# nrf9220_cellrf register map
Vendor: Nordic Semiconductor; Series: nRF92; File version: 1
CPU: CM0 r0p0, little endian, no MPU, no FPU, 2 interrupt priority bits, 33 interrupts
Registers are 32-bit, read-write, reset 0x0 unless marked. A register's access mark holds for its fields unless they carry their own. Offsets are from the block's base; [hi:lo] are bit positions; {n}, {i} and the like mark numbered series; 'fields as' and 'values as' point back to an identical list.

## RXDFE (part 2 of 2) — HALTI_RX_register_map AhmaRx Digital control register map Karhu Rx Analog control register map AhmaRx Digital control register map
Base 0x46130000
0x5A8 RX_NBPM_DC_I ro — Measured narrow band DC I.
  [15:0] DC — This is a signed value. This registers can be read after RX_NBPM_READY event is occurred.
0x5AC RX_NBPM_DC_Q ro — Measured narrow band DC Q.
  fields as RX_NBPM_DC_I
0x5B0 RX_WBPM_DATA_SEL — Wide band power meter input data selection.
  [1:0] SEL — Selects input data of wide band power meter.
    0=HBFIR1 (HB FIR 1 input); 1=HBFIR2 (HB FIR 2 input); 2=DCCOMP (DC compensator input)
0x5B4 RX_WBPM_FACTOR_L — Wide band power meter factor L.
  [2:0] FACTOR — Specifies how many bits of input data are downshifted before data is feed into wide band power meter.
    0=0bit; 1=1bit; 7=7bits
0x5B8 RX_WBPM_FACTOR_M — Wide band power meter factor M.
  [5:0] FACTOR — Number of consecutive power measurements on which max power is performed.
    0=1 measurement; 1=2 measurements; 63=64 measurements
0x5BC RX_WBPM_FACTOR_K — Wide band power meter factor K.
  [13:0] FACTOR — Number of samples considered in power and DC measurement (i.e. accumulation).
    0=1sample; 1=2samples; 0x3FFF=16384samples
0x5C0 RX_WBPM_FACTOR_N — Wide band power meter factor N.
  [3:0] FACTOR — Specifies how many bits are downshifted after power and DC accumulation.
    0=0bit; 1=1bit; 15=15bits
0x5C4 RX_WBPM_POWER ro — Measured wide band power.
  [31:0] POWER — This is a squared value. This registers can be read after RX_WBPM_READY event is occurred.
0x5C8 RX_WBPM_DC_I ro — Measured wide band DC I.
  [15:0] DC — This is a signed value. This registers can be read after RX_WBPM_READY event is occurred.
0x5CC RX_WBPM_DC_Q ro — Measured wide band DC Q.
  fields as RX_WBPM_DC_I
0x5D0 RX_SAMPLE_CNT_COMP_0 — RX sample count compare 0.
  [31:0] COMP — When this value matches internal RX sample counter, the RX_SAMPLE_CNT_COMP_0 event is generated.
0x5D4 RX_SAMPLE_CNT_CAPT_0 ro — RX sample count capture 0.
  [31:0] CAPT — The task RX_CAPT_SAMPLE_CNT_0 captures the sample counter value into this register. This registers can be read after RX_SAMPLE_CNT_CAPT_0 event is occurred.
0x5D8 RX_SAMPLE_CNT_COMP_1 — RX sample count compare 1.
  [31:0] COMP — When this value matches internal RX sample counter, the RX_SAMPLE_CNT_COMP_1 event is generated.
0x5DC RX_SAMPLE_CNT_CAPT_1 ro — RX sample count capture 1.
  [31:0] CAPT — The task RX_CAPT_SAMPLE_CNT_1 captures the sample counter value into this register. This registers can be read after RX_SAMPLE_CNT_CAPT_1 event is occurred.
0x5E0 RX_IQ_EST_ENABLE — IQ estimation enable.
  [0] ENABLE — Enable IQ estimation.
    0=Disabled; 1=Enabled
0x5E4 RX_IQ_EST_FACTOR_K — IQ estimation factor K value.
  [10:0] FACTOR — Specifies number of samples considered during the IQ estimation.
    0=1sample; 1=2samples; 0x7FF=2048samples
0x5E8 RX_IQ_EST_FACTOR_L — IQ estimation factor L value.
  [2:0] FACTOR — Specifies loop gain of the IQ correction and estimation.
    0=Gain is 1; 1=2x (Gain is 2); 7=8x (Gain is 8)
0x5EC RX_IQ_EST_AMP — IQ estimation amplitude.
  [9:0] AMP — Initialization value of IQ amplitude estimation. This value is pre-loaded to reach better and faster convergence. Used as external amplitude correction value if IQ_EST_ENABLE is zero.
0x5F0 RX_IQ_EST_AMP_READ ro — IQ estimation amplitude read.
  [9:0] AMP — Returns amplitude correction value when read.
0x5F4 RX_IQ_EST_IMAGE — IQ estimation image.
  [9:0] IMAGE — Initialization value of IQ image estimation. This value is pre-loaded to reach better and faster convergence. Used as external image correction value if IQ_EST_ENABLE is zero.
0x5F8 RX_IQ_EST_IMAGE_READ ro — IQ estimation image read.
  [9:0] IMAGE — Returns image correction value when read.
0x5FC RX_IQ_CORR_ENABLE — IQ correction enable.
  [0] ENABLE — Enable IQ correction.
    0=Disabled; 1=Enabled
0x600 RX_DIG_SPARE — Spare register for digital.
  [15:0] SPARE — Spare bits.
0x604 RX_ABB_CAL_STORE — Stored value of RX ABB RC calibration result.
  [4:0] RESULT — SW stores RC calibration value into this register.
0x608 RX_DEBUG_CORE — RX digital core debug register.
  [2:0] BYPASS — RX digital core bypass.
    0=Normal operation; 1=HB FIR 1 outputs connected to RX data outputs; 2=Int3Dec4 outputs connected to RX data outputs; 3=DecR outputs connected to RX data outputs; 4=Dec2 outputs connected to RX data outputs
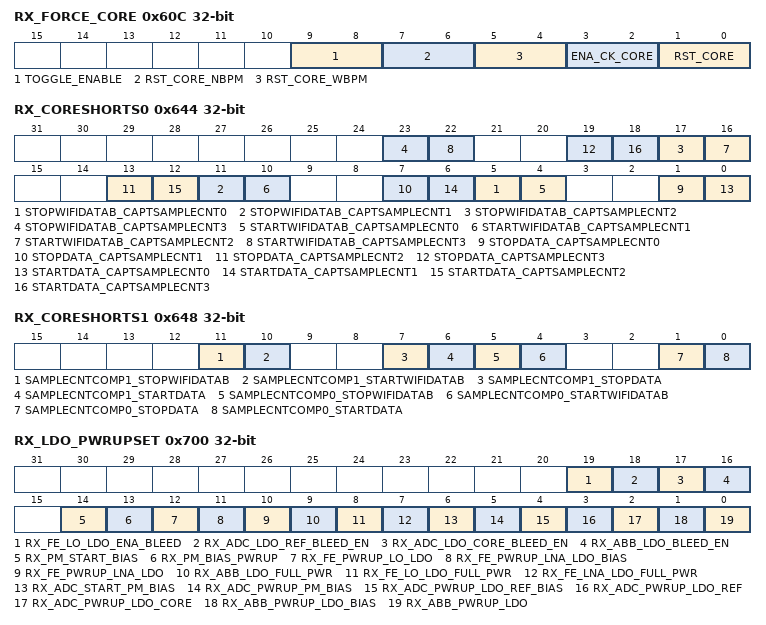
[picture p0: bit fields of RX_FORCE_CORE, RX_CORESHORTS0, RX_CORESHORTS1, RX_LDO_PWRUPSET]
0x60C RX_FORCE_CORE — RX digital core force register.
  [all] fields
    0=Normal operation; 1=NA (Not available); 2=Low (Forced to low); 3=High (Forced to high)
  [9:8] TOGGLE_ENABLE — Force toggleDelayEnable.
  [7:6] RST_CORE_NBPM — Force rstCoreNbpm.
  [5:4] RST_CORE_WBPM — Force rstCoreWbpm.
  [3:2] ENA_CK_CORE — Force enaCkCore.
  [1:0] RST_CORE — Force rstCore.
{0x610+4i} RX_DEBUG_{i}_PSEL (i=0..7) — RX debug {i} port/pin selection.
  [3:0] SELECT — Connection selection.
0x630 RX_FORCE_CK_REQ — RX debug 7 port/pin selection.
  [0] FORCE — This bit is used to force the ADC clock ON in the emulator environment. This bit is combined with RX_ADC_CK_REQ by the OR-gate.
    0=NoEffect; 1=Forced (ADC clock forced ON)
0x634 RX_SAMPLE_CNT_CAPT_2 ro — RX sample count capture 1.
  [31:0] CAPT — The task RX_CAPT_SAMPLE_CNT_2 captures the sample counter value into this register. This registers can be read after RX_SAMPLE_CNT_CAPT_2 event is occurred.
0x638 RX_SAMPLE_CNT_CAPT_3 ro — RX sample count capture 1.
  [31:0] CAPT — The task RX_CAPT_SAMPLE_CNT_3 captures the sample counter value into this register. This registers can be read after RX_SAMPLE_CNT_CAPT_3 event is occurred.
0x63C RX_NBPM_MODE — Narrow band power meter mode.
  [0] MODE — Measurement mode. The single measurement ends when K * M samples have been consumed. The continuous measurement ends when it is stopped with the stop task.
    0=Single measurement; 1=Continuous measument
0x640 RX_WBPM_MODE — Wide band power meter mode.
  [0] MODE — Measurement mode. The single measurement ends when K * M samples have been consumed. The continuous measurement ends when it is stopped with the stop task.
    0=Single measurement; 1=Continuous measurement
0x644 RX_CORESHORTS0 — Core level shortcut register.
  [all] fields
    0=Disabled; 1=Enabled
  [6n+5] STOPWIFIDATAB_CAPTSAMPLECNT{n} (n=0..3) — Shortcut between stop Wi-Fi b data and capture sample count {n} trigger.
  [6n+4] STARTWIFIDATAB_CAPTSAMPLECNT{n} (n=0..3) — Shortcut between start Wi-Fi b data and capture sample count {n} trigger.
  [6n+1] STOPDATA_CAPTSAMPLECNT{n} (n=0..3) — Shortcut between stop LTE/GNSS data and capture sample count {n} trigger.
  [6n] STARTDATA_CAPTSAMPLECNT{n} (n=0..3) — Shortcut between start LTE/GNSS data and capture sample count {n} trigger.
0x648 RX_CORESHORTS1 — Core level shortcut register.
  [all] fields
    0=Disabled; 1=Enabled
  [11] SAMPLECNTCOMP1_STOPWIFIDATAB — Short-cut between sample counter compare 1 and stop Wi-Fi b data.
  [10] SAMPLECNTCOMP1_STARTWIFIDATAB — Short-cut between sample counter compare 1 and start Wi-Fi b data.
  [7] SAMPLECNTCOMP1_STOPDATA — Short-cut between sample counter compare 1 and stop LTE/GNSS data.
  [6] SAMPLECNTCOMP1_STARTDATA — Short-cut between sample counter compare 1 and start LTE/GNSS data.
  [5] SAMPLECNTCOMP0_STOPWIFIDATAB — Short-cut between sample counter compare 0 and stop Wi-Fi b data.
  [4] SAMPLECNTCOMP0_STARTWIFIDATAB — Short-cut between sample counter compare 0 and start Wi-Fi b data.
  [1] SAMPLECNTCOMP0_STOPDATA — Short-cut between sample counter compare 0 and stop LTE/GNSS data.
  [0] SAMPLECNTCOMP0_STARTDATA — Short-cut between sample counter compare 0 and start LTE/GNSS data.
0x700 RX_LDO_PWRUPSET write-1-sets — RX and MRX LDO power up register
  [all] fields
    1=SET (Unspecified); 0=NoEffect (Unspecified)
  [19] RX_FE_LO_LDO_ENA_BLEED — LDO bleed ON
  [18] RX_ADC_LDO_REF_BLEED_EN — LDO bleed ON
  [17] RX_ADC_LDO_CORE_BLEED_EN — LDO bleed ON
  [16] RX_ABB_LDO_BLEED_EN — LDO bleed ON
  [14] RX_PM_START_BIAS — Kickstart BG_LDO_REF current
  [13] RX_PM_BIAS_PWRUP — BG_LDO_REF current up
  [12] RX_FE_PWRUP_LO_LDO — LDO power up
  [11] RX_FE_PWRUP_LNA_LDO_BIAS — LDO power up
  [10] RX_FE_PWRUP_LNA_LDO — LDO power up
  [9] RX_ABB_LDO_FULL_PWR — LDO power up
  [8] RX_FE_LO_LDO_FULL_PWR — LDO power up
  [7] RX_FE_LNA_LDO_FULL_PWR — LDO power up
  [6] RX_ADC_START_PM_BIAS — LDO power up
  [5] RX_ADC_PWRUP_PM_BIAS — LDO power up
  [4] RX_ADC_PWRUP_LDO_REF_BIAS — LDO power up
  [3] RX_ADC_PWRUP_LDO_REF — LDO power up
  [2] RX_ADC_PWRUP_LDO_CORE — LDO power up
  [1] RX_ABB_PWRUP_LDO_BIAS — LDO power up
  [0] RX_ABB_PWRUP_LDO — LDO power up
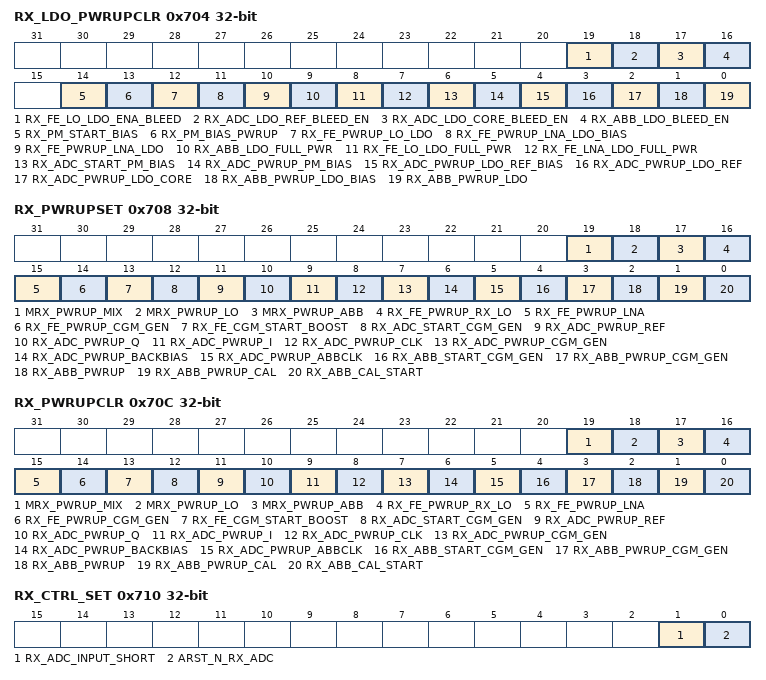
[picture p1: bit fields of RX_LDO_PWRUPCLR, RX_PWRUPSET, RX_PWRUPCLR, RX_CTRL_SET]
0x704 RX_LDO_PWRUPCLR write-1-clears — RX and MRX LDO power down register
  [all] fields
    1=CLR (Unspecified); 0=NoEffect (Unspecified)
  [19] RX_FE_LO_LDO_ENA_BLEED — LDO bleed OFF
  [18] RX_ADC_LDO_REF_BLEED_EN — LDO bleed OFF
  [17] RX_ADC_LDO_CORE_BLEED_EN — LDO bleed OFF
  [16] RX_ABB_LDO_BLEED_EN — LDO bleed OFF
  [14] RX_PM_START_BIAS — Kickstart BG_LDO_REF current OFF
  [13] RX_PM_BIAS_PWRUP — BG_LDO_REF current down
  [12] RX_FE_PWRUP_LO_LDO — LDO power down
  [11] RX_FE_PWRUP_LNA_LDO_BIAS — LDO power down
  [10] RX_FE_PWRUP_LNA_LDO — LDO power down
  [9] RX_ABB_LDO_FULL_PWR — LDO power down
  [8] RX_FE_LO_LDO_FULL_PWR — LDO power down
  [7] RX_FE_LNA_LDO_FULL_PWR — LDO power down
  [6] RX_ADC_START_PM_BIAS — LDO power down
  [5] RX_ADC_PWRUP_PM_BIAS — LDO power down
  [4] RX_ADC_PWRUP_LDO_REF_BIAS — LDO power down
  [3] RX_ADC_PWRUP_LDO_REF — LDO power down
  [2] RX_ADC_PWRUP_LDO_CORE — LDO power down
  [1] RX_ABB_PWRUP_LDO_BIAS — LDO power down
  [0] RX_ABB_PWRUP_LDO — LDO power down
0x708 RX_PWRUPSET write-1-sets — RX, MRX and GPS power up register
  [all] fields
    1=SET (Unspecified); 0=NoEffect (Unspecified)
  [19] MRX_PWRUP_MIX — Power up
  [18] MRX_PWRUP_LO — Power up
  [17] MRX_PWRUP_ABB — Power up
  [16] RX_FE_PWRUP_RX_LO — Power up
  [15] RX_FE_PWRUP_LNA — Power up
  [14] RX_FE_PWRUP_CGM_GEN — Power up
  [13] RX_FE_CGM_START_BOOST — Power up
  [12] RX_ADC_START_CGM_GEN — Power up
  [11] RX_ADC_PWRUP_REF — Power up
  [10] RX_ADC_PWRUP_Q — Power up
  [9] RX_ADC_PWRUP_I — Power up
  [8] RX_ADC_PWRUP_CLK — Power up
  [7] RX_ADC_PWRUP_CGM_GEN — Power up
  [6] RX_ADC_PWRUP_BACKBIAS — Power up
  [5] RX_ADC_PWRUP_ABBCLK — Power up
  [4] RX_ABB_START_CGM_GEN — Power up
  [3] RX_ABB_PWRUP_CGM_GEN — Power up
  [2] RX_ABB_PWRUP — Power up
  [1] RX_ABB_PWRUP_CAL — Power up
  [0] RX_ABB_CAL_START — Power up
0x70C RX_PWRUPCLR write-1-clears — RX, MRX and GPS power down register
  [all] fields
    1=CLR (Unspecified); 0=NoEffect (Unspecified)
  [19] MRX_PWRUP_MIX — Power down
  [18] MRX_PWRUP_LO — Power down
  [17] MRX_PWRUP_ABB — Power down
  [16] RX_FE_PWRUP_RX_LO — Power down
  [15] RX_FE_PWRUP_LNA — Power down
  [14] RX_FE_PWRUP_CGM_GEN — Power down
  [13] RX_FE_CGM_START_BOOST — Power down
  [12] RX_ADC_START_CGM_GEN — Power down
  [11] RX_ADC_PWRUP_REF — Power down
  [10] RX_ADC_PWRUP_Q — Power down
  [9] RX_ADC_PWRUP_I — Power down
  [8] RX_ADC_PWRUP_CLK — Power down
  [7] RX_ADC_PWRUP_CGM_GEN — Power down
  [6] RX_ADC_PWRUP_BACKBIAS — Power down
  [5] RX_ADC_PWRUP_ABBCLK — Power down
  [4] RX_ABB_START_CGM_GEN — Power down
  [3] RX_ABB_PWRUP_CGM_GEN — Power down
  [2] RX_ABB_PWRUP — Power down
  [1] RX_ABB_PWRUP_CAL — Power down
  [0] RX_ABB_CAL_START — Power down
0x710 RX_CTRL_SET write-1-sets — Misc set register
  [1] RX_ADC_INPUT_SHORT — ADC input short ON
    1=SET (Unspecified); 0=NoEffect (Unspecified)
  [0] ARST_N_RX_ADC — ADC analog reset ON
    1=SET (Unspecified); 0=NoEffect (Unspecified)
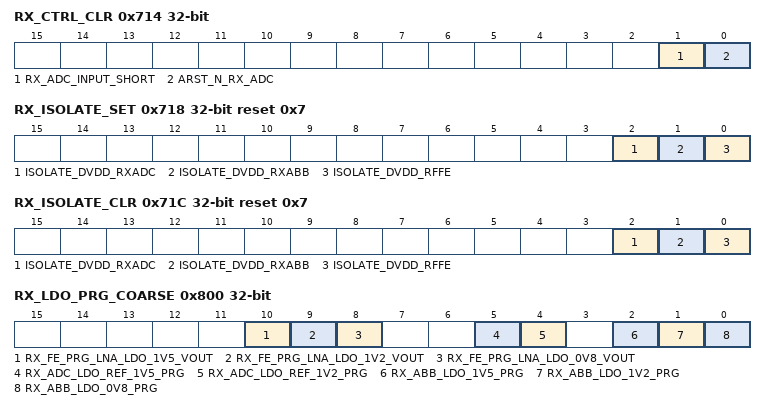
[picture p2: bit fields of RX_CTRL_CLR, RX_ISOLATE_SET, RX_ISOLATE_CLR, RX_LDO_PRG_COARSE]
0x714 RX_CTRL_CLR write-1-clears — Misc clr register
  [1] RX_ADC_INPUT_SHORT — ADC input short OFF
    1=CLR (Unspecified); 0=NoEffect (Unspecified)
  [0] ARST_N_RX_ADC — ADC analog reset OFF
    1=CLR (Unspecified); 0=NoEffect (Unspecified)
0x718 RX_ISOLATE_SET reset 0x7 write-1-sets — LS isolate set register
  [all] fields
    1=Isolate (Unspecified); 0=NoEffect (Unspecified)
  [2] ISOLATE_DVDD_RXADC — LS isolate ON
  [1] ISOLATE_DVDD_RXABB — LS isolate ON
  [0] ISOLATE_DVDD_RFFE — LS isolate ON
0x71C RX_ISOLATE_CLR reset 0x7 write-1-clears — LS isolate clr register
  [all] fields
    1=Isolate (Unspecified); 0=NoEffect (Unspecified)
  [2] ISOLATE_DVDD_RXADC — LS isolate OFF
  [1] ISOLATE_DVDD_RXABB — LS isolate OFF
  [0] ISOLATE_DVDD_RFFE — LS isolate OFF
0x800 RX_LDO_PRG_COARSE — RX and MRX LDO coarse voltage tuning
  [10] RX_FE_PRG_LNA_LDO_1V5_VOUT — LDO program
    0=default (Unspecified)
  [9] RX_FE_PRG_LNA_LDO_1V2_VOUT — LDO program
    1=default (Unspecified)
  [8] RX_FE_PRG_LNA_LDO_0V8_VOUT — LDO program
    0=default (Unspecified)
  [5] RX_ADC_LDO_REF_1V5_PRG — LDO program
    1=default (Unspecified)
  [4] RX_ADC_LDO_REF_1V2_PRG — LDO program
    0=default (Unspecified)
  [2] RX_ABB_LDO_1V5_PRG — LDO program
    0=default (Unspecified)
  [1] RX_ABB_LDO_1V2_PRG — LDO program
    1=default (Unspecified)
  [0] RX_ABB_LDO_0V8_PRG — LDO program
    0=default (Unspecified)
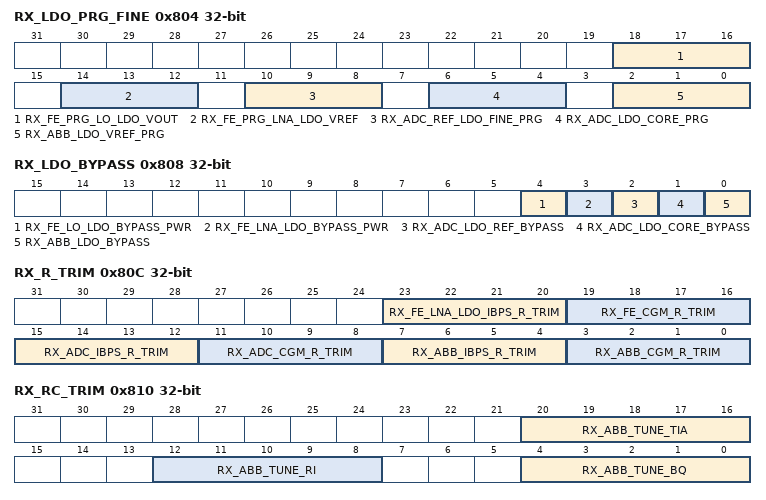
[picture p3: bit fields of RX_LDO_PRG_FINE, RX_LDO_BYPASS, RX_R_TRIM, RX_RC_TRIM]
0x804 RX_LDO_PRG_FINE — RX and MRX LDO fine voltage tuning
  [18:16] RX_FE_PRG_LO_LDO_VOUT — LDO program
    3=0p884V (default); 2=0p858V (Unspecified); 1=0p831V (Unspecified); 0=0p804V (Unspecified); 7=0p777V (Unspecified); 6=0p750V (Unspecified); 5=0p724V (Unspecified); 4=0p697V (Unspecified)
  [14:12] RX_FE_PRG_LNA_LDO_VREF — LDO program
    3=1p31V (default); 2=1p27V (Unspecified); 1=1p23V (Unspecified); 0=1p19V (Unspecified); 7=1p15V (Unspecified); 6=1p11V (Unspecified); 5=1p07V (Unspecified); 4=1p03V (Unspecified)
  [10:8] RX_ADC_REF_LDO_FINE_PRG — LDO program
    3=1p66V (default); 2=1p61V (Unspecified); 1=1p56V (Unspecified); 0=1p51V (Unspecified); 7=1p46V (Unspecified); 6=1p41V (Unspecified); 5=1p36V (Unspecified); 4=1p31V (Unspecified)
  [6:4] RX_ADC_LDO_CORE_PRG — LDO program
    values as RX_FE_PRG_LO_LDO_VOUT
  [2:0] RX_ABB_LDO_VREF_PRG — LDO program
    values as RX_FE_PRG_LNA_LDO_VREF
0x808 RX_LDO_BYPASS — RX and MRX LDO bypass
  [all] fields
    0=always (Unspecified)
  [4] RX_FE_LO_LDO_BYPASS_PWR — LDO program
  [3] RX_FE_LNA_LDO_BYPASS_PWR — LDO program
  [2] RX_ADC_LDO_REF_BYPASS — LDO program
  [1] RX_ADC_LDO_CORE_BYPASS — LDO program
  [0] RX_ABB_LDO_BYPASS — LDO program
0x80C RX_R_TRIM — RX resistor trimming
  [all] fields
    0=default (Unspecified)
  [23:20] RX_FE_LNA_LDO_IBPS_R_TRIM — Resistor tuning word 2 s complement
  [19:16] RX_FE_CGM_R_TRIM — Resistor tuning word 2 s complement
  [15:12] RX_ADC_IBPS_R_TRIM — Resistor tuning word 2 s complement
  [11:8] RX_ADC_CGM_R_TRIM — Resistor tuning word 2 s complement
  [7:4] RX_ABB_IBPS_R_TRIM — Resistor tuning word 2 s complement
  [3:0] RX_ABB_CGM_R_TRIM — Resistor tuning word 2 s complement
0x810 RX_RC_TRIM — RX ABB RC calibration control
  [20:16] RX_ABB_TUNE_TIA — Resistor tuning word
    20=default (Unspecified)
  [12:8] RX_ABB_TUNE_RI — Resistor tuning word
    23=default (Unspecified)
  [4:0] RX_ABB_TUNE_BQ — Resistor tuning word
    20=default (Unspecified)
0x814 RX_RFGAIN — RX gain control
  [6:0] RX_FE_GAIN — Gain control of RX_FE
    127=MaxM0dB (Unspecified); 63=MaxM6dB (Unspecified); 31=MaxM12dB (Unspecified); 15=MaxM18dB (Unspecified); 7=MaxM24dB (Unspecified); 3=MaxM30dB (Unspecified); 1=MaxM36dB (Unspecified); 0=MaxM42dB (Unspecified)
0x818 RX_RFLNASEL — RX LNA input selection
  [2:0] RX_FE_SEL_LNA_INPUT — Select LNA input
    1=input1 (Unspecified); 2=input2 (Unspecified); 4=input3 (Unspecified)
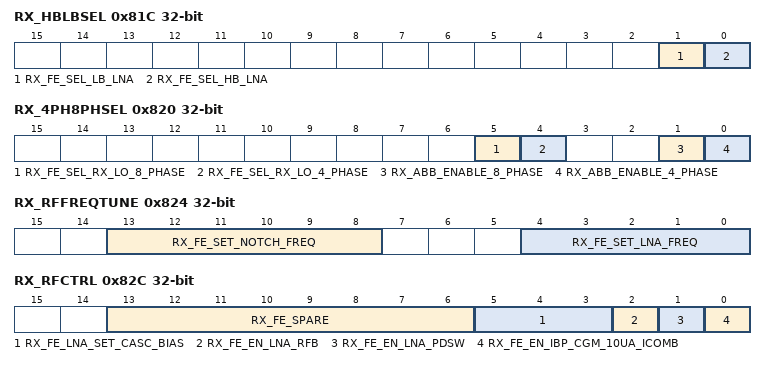
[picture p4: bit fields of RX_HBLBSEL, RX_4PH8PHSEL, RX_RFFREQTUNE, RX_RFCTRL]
0x81C RX_HBLBSEL — RX HB / LB path selection
  [1] RX_FE_SEL_LB_LNA — Select LB signal path
    1=LB_ON (Unspecified); 0=LB_OFF (Unspecified)
  [0] RX_FE_SEL_HB_LNA — Select HB signal path
    1=HB_ON (Unspecified); 0=HB_OFF (Unspecified)
0x820 RX_4PH8PHSEL — RX 4phase / 8phase selection
  [5] RX_FE_SEL_RX_LO_8_PHASE — Select 8 phase
    1=8phaseON (Unspecified); 0=8phaseOFF (Unspecified)
  [4] RX_FE_SEL_RX_LO_4_PHASE — Select 4 phase
    1=4phaseON (Unspecified); 0=4phaseOFF (Unspecified)
  [1] RX_ABB_ENABLE_8_PHASE — Select 8 phase
    1=8phaseON (Unspecified); 0=8phaseOFF (Unspecified)
  [0] RX_ABB_ENABLE_4_PHASE — Select 4 phase
    1=4phaseON (Unspecified); 0=4phaseOFF (Unspecified)
0x824 RX_RFFREQTUNE — RX LNA frequency tuning
  [13:8] RX_FE_SET_NOTCH_FREQ — Notch frequency control word
    63=Fmax (Unspecified); 0=Fmin (Unspecified)
  [4:0] RX_FE_SET_LNA_FREQ — RF frequency control word
    31=Fmax (Unspecified); 0=Fmin (Unspecified)
0x828 RX_RFCGMTUNE — RX LNA bias current tuning
  [4:0] RX_FE_SEL_IBP_CGM_UA — Control of output current of RX_FE bias circuit. Idd = Codeword x 10 uA Default around 25
0x82C RX_RFCTRL — RX RF general control
  [13:6] RX_FE_SPARE — RF spareRibs
  [5:3] RX_FE_LNA_SET_CASC_BIAS — Cascode bias control for debugging
    3=Default (Unspecified)
  [2] RX_FE_EN_LNA_RFB — Resistive feedback enable
    1=ON (Unspecified); 0=OFF (Unspecified)
  [1] RX_FE_EN_LNA_PDSW — Inactive inputs coupled to GND
    1=GND (Unspecified); 0=HiZ (Unspecified)
  [0] RX_FE_EN_IBP_CGM_10UA_ICOMB — Enable current combiner
    0=OFF (Default); 1=ON (Unspecified)
0x830 RX_EXTMATCHING — RX external matching
  [0] RX_FE_EN_LB_LNA_EXT_MATCHING — LNA requires external matching
    1=ExtenalMacting (Unspecified); 0=OnchipMatching (Unspecified)
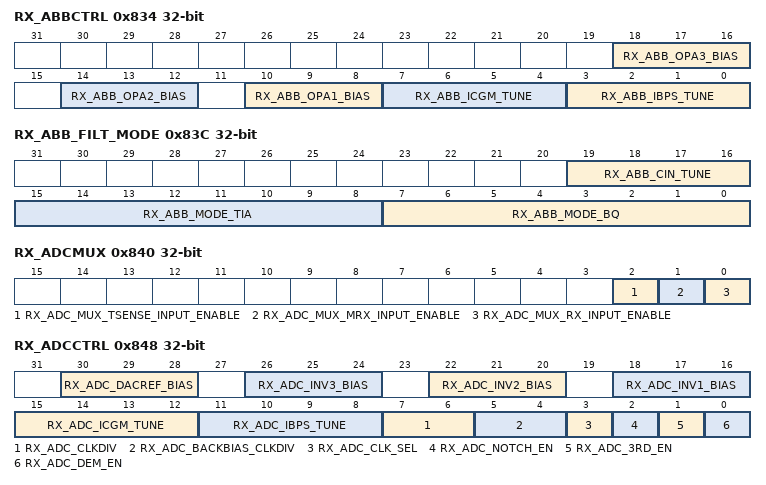
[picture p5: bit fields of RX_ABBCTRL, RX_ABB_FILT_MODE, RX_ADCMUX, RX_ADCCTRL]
0x834 RX_ABBCTRL — RX ABB general control
  [18:16] RX_ABB_OPA3_BIAS — ABB OPA3 bias current
    0=Idd4uA (Default); 1=Idd6uA (Unspecified); 2=Idd8uA (Unspecified); 3=Idd10uA (Unspecified); 4=Idd12uA (Unspecified); 5=Idd14uA (Unspecified); 6=Idd16uA (Unspecified); 7=Idd18uA (Unspecified)
  [14:12] RX_ABB_OPA2_BIAS — ABB OPA2 bias current
    values as RX_ABB_OPA3_BIAS
  [10:8] RX_ABB_OPA1_BIAS — ABB OPA1 bias current
    values as RX_ABB_OPA3_BIAS
  [7:4] RX_ABB_ICGM_TUNE — PTAT current
    3=default (Unspecified)
  [3:0] RX_ABB_IBPS_TUNE — Temperature independent current
    3=default (Unspecified)
0x838 RX_ABBSPARE — RX ABB spare bits
  [7:0] RX_ABB_SPARE — RXABB spareRibs
0x83C RX_ABB_FILT_MODE — RX ABB bandwidth/mode control
  [19:16] RX_ABB_CIN_TUNE — RXABB input cap ctrl
    0=OFF (Default); 3=MAX (Unspecified)
  [15:8] RX_ABB_MODE_TIA — RXABB TIA frequency ctrl
    230=NB1 (Unspecified); 75=M1narrow (Unspecified); 53=M1wide (Unspecified); 27=5MHz (Unspecified); 15=10MHz (Unspecified)
  [7:0] RX_ABB_MODE_BQ — RXABB BQ frequency ctrl
    values as RX_ABB_MODE_TIA
0x840 RX_ADCMUX — RX ADC input mux selection
  [2] RX_ADC_MUX_TSENSE_INPUT_ENABLE — PMMEAS
    1=ENABLE_PMMEAS (Unspecified); 0=DISABLE (Unspecified)
  [1] RX_ADC_MUX_MRX_INPUT_ENABLE — MRX
    1=ENABLE_MRX (Unspecified); 0=DISABLE (Unspecified)
  [0] RX_ADC_MUX_RX_INPUT_ENABLE — RX
    1=ENABLE_RX (Unspecified); 0=DISABLE (Unspecified)
0x844 RX_ADC_INPUT_ATTN — RX ADC input attenuator
  [0] RX_ADC_INPUT_ATTN — Enables 2.5dB input signal attenuation
    1=ENABLE (Unspecified); 0=DISABLE (Unspecified)
0x848 RX_ADCCTRL — RX ADC general controls
  [30:28] RX_ADC_DACREF_BIAS — ADC DACREF bias current
    0=Idd100uA (Fs 19.2 MHz); 1=Idd120uA (Fs 38.4 MHz); 3=Idd160uA (Fs 76.8 MHz); 5=Idd200uA (Fs 153.6 MHz); 7=Idd240uA (Fs 307.2 MHz)
  [26:24] RX_ADC_INV3_BIAS — ADC INV3 bias current
    0=Idd20uA (Fs 19.2 MHz); 1=Idd40uA (Fs 38.4 MHz); 3=Idd80uA (Fs 76.8 MHz); 5=Idd120uA (Fs 153.6 MHz); 7=Idd180uA (Fs 307.2 MHz)
  [22:20] RX_ADC_INV2_BIAS — ADC INV2 bias current
    0=Idd10uA (Fs 19.2 MHz); 1=Idd20uA (Fs 38.4 MHz); 3=Idd40uA (Fs 76.8 MHz); 5=Idd60uA (Fs 153.6 MHz); 7=Idd80uA (Fs 307.2 MHz)
  [18:16] RX_ADC_INV1_BIAS — ADC INV1 bias current
    values as RX_ADC_INV3_BIAS
  [15:12] RX_ADC_ICGM_TUNE — PTAT current
    3=Default (Unspecified)
  [11:8] RX_ADC_IBPS_TUNE — Temperature independent current
    3=Default (Unspecified)
  [7:6] RX_ADC_CLKDIV — Division ratio of ADC sampling clock. Default input clock is 307.2 MHz
    0=DiVBy1 (Unspecified); 1=DivBy2 (Unspecified); 2=DivBy4 (Unspecified); 3=DivBy8 (Unspecified)
  [5:4] RX_ADC_BACKBIAS_CLKDIV — Divides backbias and ABB clocks from ADC sampling clock. Output clock frequency must be 38.4 MHz.
    values as RX_ADC_CLKDIV
  [3] RX_ADC_CLK_SEL — Default MCPLL or alternative GPLL clock source
    1=GPLL (Default); 0=MCPLL (Unspecified)
  [2] RX_ADC_NOTCH_EN — Notch enabled
    1=ENABLE (Unspecified); 0=DISABLE (Unspecified)
  [1] RX_ADC_3RD_EN — 3rd order enabled
    1=ENABLE (Unspecified); 0=DISABLE (Unspecified)
  [0] RX_ADC_DEM_EN — DEM enabled
    1=ENABLE (Unspecified); 0=DISABLE (Unspecified)
0x84C RX_ADCSPARE — RX ADC spare bits
  [7:0] RX_ADC_SPARE — RX ADC spareRibs
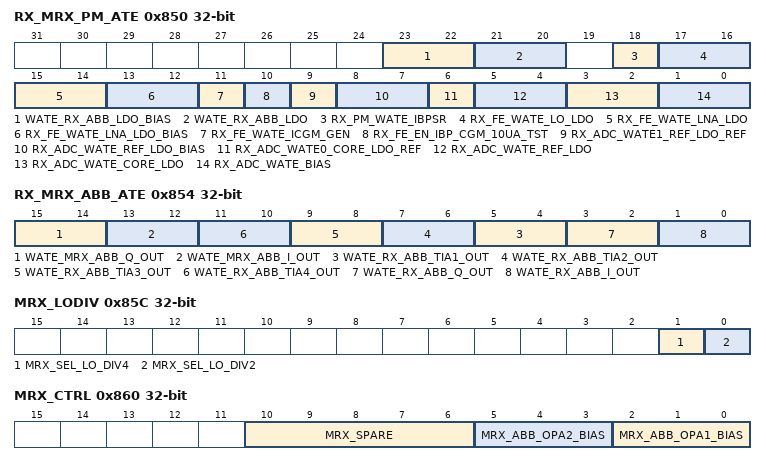
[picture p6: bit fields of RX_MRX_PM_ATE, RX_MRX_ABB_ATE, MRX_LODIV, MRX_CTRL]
0x850 RX_MRX_PM_ATE — RX and MRX LDO and bias ATE controls
  [23:22] WATE_RX_ABB_LDO_BIAS — RXABB WATE control
    0=OFF (00 OFF); 1=WATB0 (01 LDO 1.2V bias gen IBPS to WATB0); 2=WATB1 (10 LDO 1.2V INN_BIAS=FB_OUT_BIAS to WATB1)
  [21:20] WATE_RX_ABB_LDO — RXABB WATE control
    0=OFF (00 OFF); 1=WATB0 (01 LDO_OUT to WATB0); 2=WATB1 (10 LDO_VOUT_RDIV to WATB1)
  [18] RX_PM_WATE_IBPSR — RXPM WATE control
    0=OFF (0 OFF); 1=WATB (1 VREF to WATE1)
  [17:16] RX_FE_WATE_LO_LDO — RXFE WATE control
    0=OFF (00 OFF); 1=WATB0 (01 AVDD_0V8_RX_LO to WATB0); 2=WATB1 (10 INP_INT to WATB1)
  [15:14] RX_FE_WATE_LNA_LDO — RXFE WATE control
    values as WATE_RX_ABB_LDO
  [13:12] RX_FE_WATE_LNA_LDO_BIAS — RXFE WATE control
    0=OFF (00 OFF); 1=WATB0 (01 LNA LDO 1V2 IBPS 10 uA to WATB0); 2=WATB1 (10 LNA LDO 1V2 INN_BIAS=FB_OUT_BIAS to WATB1)
  [11] RX_FE_WATE_ICGM_GEN — RXFE WATE control
    0=OFF (0 OFF); 1=WATB (1 10-uA CGM to WATB1)
  [10] RX_FE_EN_IBP_CGM_10UA_TST — RXFE WATE control
    0=OFF (0 OFF); 1=WATB0 (Enable 10-uA CGM test output current)
  [9] RX_ADC_WATE1_REF_LDO_REF — RXADC WATE control
    0=OFF (0 OFF); 1=WATB (1 REF LDO 1.5V voltage reference, IBPSR_10UA-pin to WATB1)
  [8:7] RX_ADC_WATE_REF_LDO_BIAS — RXADC WATE control
    0=OFF (00 OFF); 1=WATB0 (01 REF LDO 1.5V bias gen IBPS to WATB0); 2=WATB1 (10 REF LDO 1.5V INN_BIAS=FB_OUT_BIAS to WATB1)
  [6] RX_ADC_WATE0_CORE_LDO_REF — RXADC WATE control
    0=OFF (0 OFF); 1=WATB0 (1 CORE LDO 0.8V voltage reference, IBPSR_10UA-pin to WATB0)
  [5:4] RX_ADC_WATE_REF_LDO — RXADC WATE control
    0=OFF (00 OFF); 1=WATB0 (01 LDO_OUT to WATB0); 2=WATB1 (10 LDO_VOUT_R_DIV to WATB1)
  [3:2] RX_ADC_WATE_CORE_LDO — RXADC WATE control
    0=OFF (00 OFF); 1=WATB0 (01 CORE_LDO_OUT_0V8_RX_ADC to WATB0); 2=WATB1 (10 CORE LDO 0.8V Ref voltage to WATB1)
  [1:0] RX_ADC_WATE_BIAS — RXADC WATE control
    0=OFF (00 OFF); 1=WATB0 (01 CGM current, CGM IBP_CGM_10UA_TST-pin to WATB0); 2=WATB1 (10 ICOMP current, TST_IBCOMB_10UA-pin to WATB1)
0x854 RX_MRX_ABB_ATE — RX and MRX ABB ATE controls
  [15:14] WATE_MRX_ABB_Q_OUT — RXABB WATE control
    0=OFF (00 OFF); 1=WATB0 (01 MRXABB_Q_OUTN to WATB0); 2=WATB1 (10 MRXABB_Q_OUTP to WATB1)
  [13:12] WATE_MRX_ABB_I_OUT — RXABB WATE control
    0=OFF (00 OFF); 1=WATB0 (01 MRXABB_I_OUTN to WATB0); 2=WATB1 (10 MRXABB_I_OUTP to WATB1)
  [2n+3:2n+2] WATE_RX_ABB_TIA{n}_OUT (n=1..4) — RXABB WATE control
    0=OFF (00 OFF); 1=WATB0 (01 RXTIA{n}_OUTN to WATB0); 2=WATB1 (10 RXTIA{n}_OUTP to WATB1)
  [3:2] WATE_RX_ABB_Q_OUT — RXABB WATE control
    0=OFF (00 OFF); 1=WATB0 (01 RXABB_Q_OUTN to WATB0); 2=WATB1 (10 RXABB_Q_OUTP to WATB1)
  [1:0] WATE_RX_ABB_I_OUT — RXABB WATE control
    0=OFF (00 OFF); 1=WATB0 (01 RXABB_I_OUTN to WATB0); 2=WATB1 (10 RXABB_I_OUTP to WATB1)
0x858 MRX_RFGAIN — MRX gain controls
  [4:0] MRX_GAIN — Gain control of MRX
    31=MaxM0dB (Unspecified); 15=MaxM6dB (Unspecified); 7=MaxM12dB (Unspecified); 3=MaxM18dB (Unspecified); 1=MaxM24dB (Unspecified); 0=MaxM30dB (Unspecified)
0x85C MRX_LODIV — MRX LO divider ratio selection
  [1] MRX_SEL_LO_DIV4 — Div by 4
    1=DivBy4ON (Unspecified); 0=DivBy4OFF (Unspecified)
  [0] MRX_SEL_LO_DIV2 — Div by 2
    1=DivBy2ON (Unspecified); 0=DivBy2OFF (Unspecified)
0x860 MRX_CTRL — MRX general controls
  [10:6] MRX_SPARE — Resistive feedback enable
    1=ON (Unspecified); 0=OFF (Unspecified)
  [5:3] MRX_ABB_OPA2_BIAS — ABB OPA2 bias current
    0=Idd4uA (default); 1=Idd6uA (Unspecified); 2=Idd8uA (Unspecified); 3=Idd10uA (Unspecified); 4=Idd12uA (Unspecified); 5=Idd14uA (Unspecified); 6=Idd16uA (Unspecified); 7=Idd18uA (Unspecified)
  [2:0] MRX_ABB_OPA1_BIAS — ABB OPA1 bias current
    values as MRX_ABB_OPA2_BIAS
0x904 WIFI_DATAENABLEB — Wi-Fi b data enable
  [0] ENABLE — This bit controls the sync reset signal of the RX Wi-Fi b data interface.
    0=Disabled; 1=Enabled
0x90C WIFI_CLKENABLEB — Wi-Fi b clock enable
  [0] ENABLE — This bit enables the RX Wi-Fi b data interface clock.
    0=Disabled; 1=Enabled
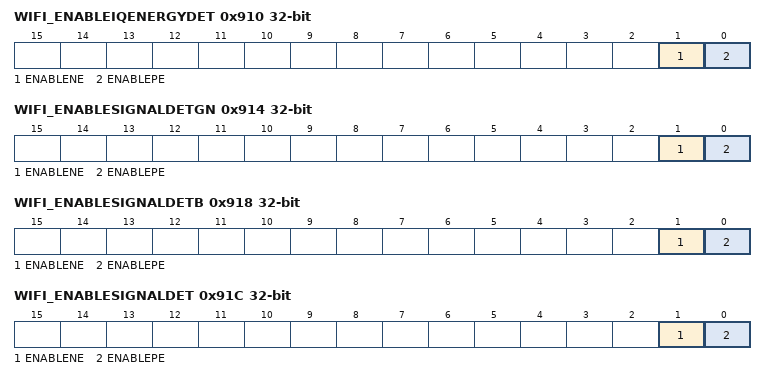
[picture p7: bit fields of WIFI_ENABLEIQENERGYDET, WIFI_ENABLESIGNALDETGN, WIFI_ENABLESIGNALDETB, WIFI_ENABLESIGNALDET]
0x910 WIFI_ENABLEIQENERGYDET — Enable IQ energy detect monitoring.
  [1] ENABLENE — Enables the generation of an event on the negative edge of the IQ energy detect signal.
    0=Disabled; 1=Enabled
  [0] ENABLEPE — Enables the generation of an event on the positive edge of the IQ energy detect signal.
    0=Disabled; 1=Enabled
0x914 WIFI_ENABLESIGNALDETGN — Enable Wi-Fi g/n signal detect monitoring.
  [1] ENABLENE — Enables the generation of an event on the negative edge of the Wi-Fi g/n signal detect signal.
    0=Disabled; 1=Enabled
  [0] ENABLEPE — Enables the generation of an event on the positive edge of the Wi-Fi g/n signal detect signal.
    0=Disabled; 1=Enabled
0x918 WIFI_ENABLESIGNALDETB — Enable Wi-Fi b signal detect monitoring.
  [1] ENABLENE — Enables the generation of an event on the negative edge of the Wi-Fi b signal detect signal.
    0=Disabled; 1=Enabled
  [0] ENABLEPE — Enables the generation of an event on the positive edge of the Wi-Fi b signal detect signal.
    0=Disabled; 1=Enabled
0x91C WIFI_ENABLESIGNALDET — Enable Wi-Fi signal detect monitoring.
  [1] ENABLENE — Enables the generation of an event on the negative edge of the Wi-Fi signal (g/n or b) signal detect signal.
    0=Disabled; 1=Enabled
  [0] ENABLEPE — Enables the generation of an event on the positive edge of the Wi-Fi signal (g/n or b) detect signal.
    0=Disabled; 1=Enabled
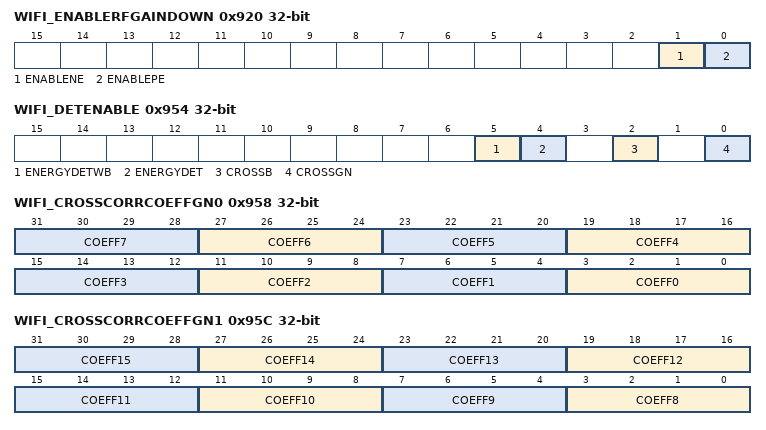
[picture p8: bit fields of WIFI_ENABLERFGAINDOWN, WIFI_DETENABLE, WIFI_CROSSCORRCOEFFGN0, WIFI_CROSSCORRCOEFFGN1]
0x920 WIFI_ENABLERFGAINDOWN — Enable RF gain down signal monitoring.
  [1] ENABLENE — Enables the generation of an event on the negative edge of the RF gain down signal.
    0=Disabled; 1=Enabled
  [0] ENABLEPE — Enables the generation of an event on the positive edge of the RF gain down signal.
    0=Disabled; 1=Enabled
0x924 WIFI_FGAFINESCALE — Fine scale value for fast gain approximation.
  [4:0] SCALE — Fast gain approximation block calculates the result in register WIFI_FGAFINERESULT and WIFI_FGACOARSERESULT based on the incoming data, this register and register WIFI_FGACOARSESCALE.
0x928 WIFI_FGACOARSESCALE — Coarse scale value for fast gain approximation.
  [4:0] SCALE — Fast gain approximation block calculates the result in register WIFI_FGAFINERESULT and WIFI_FGACOARSERESULT based on the incoming data, this register and register WIFI_FGAFINESCALE.
0x92C WIFI_FGAFINERESULT ro — Fine result of fast gain approximation.
  [7:0] RESULT — The value of this register is updated with the RX_LATCHREADREG task. SW can read this value and write it to the RX_SCALER_FINE_GAIN register.
0x930 WIFI_FGACOARSERESULT ro — Coarse result of fast gain approximation.
  [4:0] RESULT — The value of this register is updated with the RX_LATCHREADREG task. SW can read this value and write it to the RX_SCALER_COARSE_GAIN register.
0x934 WIFI_AGCTHRSCROSSGN — AGC threshold for Wi-Fi g/n cross-correlation.
  [17:0] THRS — The value of this register is used in the RF gain down comparator if this register is selected with the WIFI_AGCMODEGN register and the Wi-Fi g/n signal is detected.
0x940 WIFI_AGCTHRSCROSSB — AGC threshold for Wi-Fi b cross-correlation.
  [17:0] THRS — The value of this register is used in the RF gain down comparator if this register is selected with the WIFI_AGCMODEB register and the Wi-Fi b signal is detected.
0x94C WIFI_SIGNALDETMODEGN — Wi-Fi g/n signal detection mode.
  [2:0] MODE — This register determines which correlator is used to detect the Wi-Fi g/n signal.
    0=Cross-correlator; 4=Disabled
0x950 WIFI_SIGNALDETMODEB — Wi-Fi b signal detection mode.
  [2:0] MODE — This register determines which correlator is used to detect the WiFi b signal.
    0=Cross-correlator; 4=Disabled
0x954 WIFI_DETENABLE — Wi-Fi detection enable
  [all] fields
    0=Disabled; 1=Enabled
  [5] ENERGYDETWB — Enable Wi-Fi wide band energy detection.
  [4] ENERGYDET — Enable Wi-Fi energy detection.
  [2] CROSSB — Enable Wi-Fi b cross detection.
  [0] CROSSGN — Enable Wi-Fi g/n cross detection.
0x958 WIFI_CROSSCORRCOEFFGN0 — Wi-Fi g/n cross-correlator FIR filter coefficients.
  [4n+3:4n] COEFF{n} (n=0..7) — FIR coefficient {n} (signed value).
0x95C WIFI_CROSSCORRCOEFFGN1 — Wi-Fi g/n cross-correlator FIR filter coefficients.
  [4n-29:4n-32] COEFF{n} (n=8..15) — FIR coefficient {n} (signed value).
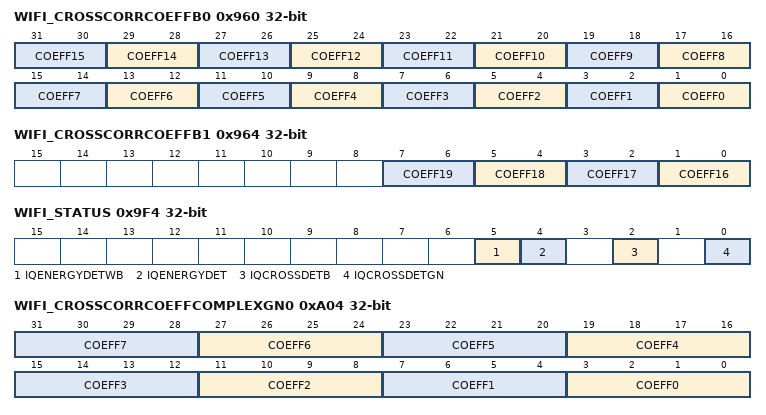
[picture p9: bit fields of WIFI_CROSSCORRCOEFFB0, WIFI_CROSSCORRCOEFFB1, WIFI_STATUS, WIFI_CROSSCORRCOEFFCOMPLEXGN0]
0x960 WIFI_CROSSCORRCOEFFB0 — Wi-Fi b cross-correlator FIR filter coefficients.
  [2n+1:2n] COEFF{n} (n=0..15) — FIR coefficient {n} (signed value).
0x964 WIFI_CROSSCORRCOEFFB1 — Wi-Fi b cross-correlator FIR filter coefficients.
  [2n-31:2n-32] COEFF{n} (n=16..19) — FIR coefficient {n} (signed value).
0x968 WIFI_CROSSTHRSGAINGN — Gain control for Wi-Fi g/n cross-correlation threshold filter.
  [3:0] GAIN
0x96C WIFI_CROSSTHRSGAINB — Gain control for Wi-Fi b cross-correlation threshold filter.
  [3:0] GAIN
0x970 WIFI_CROSSTHRSMINGN — Minimum value of the output of the Wi-Fi g/n cross-correlation threshold filter.
  [17:0] MIN
0x974 WIFI_CROSSTHRSMINB — Minimum value of the output of the Wi-Fi b cross-correlation threshold filter.
  [17:0] MIN
0x978 WIFI_CROSSTHRSMAXGN — Maximum value of the output of the Wi-Fi g/n cross-correlation threshold filter.
  [17:0] MAX
0x97C WIFI_CROSSTHRSMAXB — Maximum value of the output of the Wi-Fi b cross-correlation threshold filter.
  [17:0] MAX
0x980 WIFI_CROSSPULSEFIRSELGN — Sensitivity adjustment for pulse detection FIR in Wi-Fi g/n cross-correlation.
  [2:0] SEL
0x984 WIFI_CROSSPULSEFIRSELB — Sensitivity adjustment for pulse detection FIR in Wi-Fi b cross-correlation.
  [2:0] SEL
0x988 WIFI_CROSSPULSETHRSGN — Scaling value for pulse detection FIR in Wi-Fi g/n cross-correlation.
  [3:0] THRS
0x98C WIFI_CROSSPULSETHRSB — Scaling value for pulse detection FIR in Wi-Fi b cross-correlation.
  [3:0] THRS
0x9B8 WIFI_ENERGYDETTHRSN — Scaling value for energy detector threshold filter.
  [3:0] THRS
0x9BC WIFI_ENERGYDETLOWGAIN — Lower gain for energy detector threshold filter.
  [3:0] GAIN
0x9C0 WIFI_ENERGYDETHIGHGAIN — Higher gain for energy detector threshold filter.
  [3:0] GAIN
0x9C4 WIFI_ENERGYDETTHRSMIN — Minimum value of the output of the energy detector threshold filter.
  [18:0] MIN
0x9C8 WIFI_ENERGYDETTHRSMAX — Maximum value of the output of the energy detector threshold filter.
  [18:0] MAX
0x9CC WIFI_DATAIQCROSSCORRGN ro — Wi-Fi g/n cross-correlation output.
  [18:0] DATA
0x9D0 WIFI_DATAIQCROSSCORRB ro — Wi-Fi b cross-correlation output.
  [18:0] DATA
0x9D4 WIFI_DATAIQCROSSTHRSGN ro — Wi-Fi g/n cross-correlation threshold filter output.
  [17:0] DATA
0x9D8 WIFI_DATAIQCROSSTHRSB ro — Wi-Fi b cross-correlation threshold filter output.
  [17:0] DATA
0x9EC WIFI_IQENERGY ro — Energy detector RMS output.
  [18:0] DATA
0x9F0 WIFI_IQENERGYFILT ro — Energy detector threshold filter output.
  [18:0] DATA
0x9F4 WIFI_STATUS ro
  [5] IQENERGYDETWB — Wide band energy detector detection signal.
  [4] IQENERGYDET — Energy detector detection signal.
  [2] IQCROSSDETB — Wi-Fi b cross-correlation detection signal.
  [0] IQCROSSDETGN — Wi-Fi g/n cross-correlation detection signal.
0x9F8 WIFI_DATASCALER
  [2:0] SCALER — Scaling control of incoming data to the Wi-Fi detector.
    {v}=ShiftBy{v} ({v}: Shift-right by {v}) (v=0..7)
0x9FC WIFI_CROSSCORRMODEGN — Wi-Fi g/n cross-correlator mode
  [0] MODE — This register is used to select whether the cross-correlator is in normal or complex mode.
    0=Normal (0: Normal mode); 1=Complex (1: Complex mode)
0xA04 WIFI_CROSSCORRCOEFFCOMPLEXGN0 — Wi-Fi g/n cross-correlator complex FIR filter coefficients.
  [4n+3:4n] COEFF{n} (n=0..7) — FIR coefficient {n} (signed value).
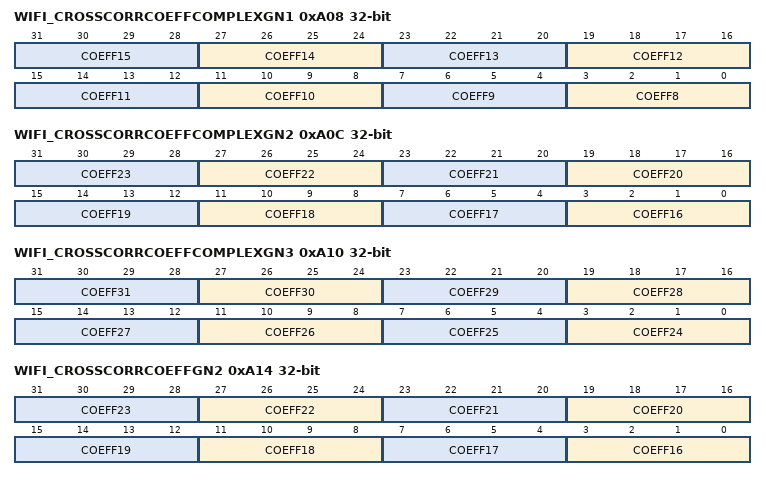
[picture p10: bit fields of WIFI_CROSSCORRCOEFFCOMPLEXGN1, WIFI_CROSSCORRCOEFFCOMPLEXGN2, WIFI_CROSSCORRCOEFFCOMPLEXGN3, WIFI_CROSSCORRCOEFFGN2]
0xA08 WIFI_CROSSCORRCOEFFCOMPLEXGN1 — Wi-Fi g/n cross-correlator complex FIR filter coefficients.
  fields as WIFI_CROSSCORRCOEFFGN1
0xA0C WIFI_CROSSCORRCOEFFCOMPLEXGN2 — Wi-Fi g/n cross-correlator complex FIR filter coefficients.
  [4n-61:4n-64] COEFF{n} (n=16..23) — FIR coefficient {n} (signed value).
0xA10 WIFI_CROSSCORRCOEFFCOMPLEXGN3 — Wi-Fi g/n cross-correlator complex FIR filter coefficients.
  [4n-93:4n-96] COEFF{n} (n=24..31) — FIR coefficient {n} (signed value).
0xA14 WIFI_CROSSCORRCOEFFGN2 — Wi-Fi g/n cross-correlator FIR filter coefficients.
  fields as WIFI_CROSSCORRCOEFFCOMPLEXGN2
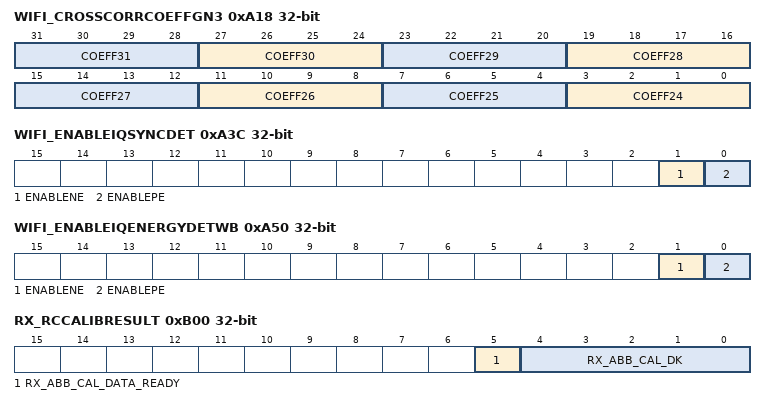
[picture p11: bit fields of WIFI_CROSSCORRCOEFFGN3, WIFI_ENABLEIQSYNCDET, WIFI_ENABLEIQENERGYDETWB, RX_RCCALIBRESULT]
0xA18 WIFI_CROSSCORRCOEFFGN3 — Wi-Fi g/n cross-correlator FIR filter coefficients.
  fields as WIFI_CROSSCORRCOEFFCOMPLEXGN3
0xA1C WIFI_DECTBMODE — DECTB mode
  [0] MODE
    0=Beta1 (0: Beta is 1); 1=Beta2 (1: Beta is 2)
0xA20 WIFI_CROSSTHRSFILTINGN — Input selection of the Wi-Fi g/n cross-correlation threshold filter.
  [0] SEL — Threshold filter input selection.
    0=Cross (0:Cross correlator output); 1=Abs (1: Absolute value of I and Q)
0xA24 WIFI_CROSSCORRENE — Enable cross-correlation enhancement.
  [0] ENABLE
    0=Disabled (0: Disabled); 1=Enabled (1: Enabled)
0xA2C WIFI_CROSSTHRSSCALEE — Scaling control for cross-correlation enhancement threshold filter.
  [6:0] SCALE
0xA30 WIFI_CROSSTHRSGAINE — Gain control for cross-correlation enhancement threshold filter.
  [6:0] GAIN
0xA34 WIFI_CROSSTHRSMINE — Minimum value of the output of the cross-correlation enhancement threshold filter.
  [17:0] MIN
0xA38 WIFI_CROSSPULSEFIRSELE — Sensitivity adjustment for pulse detection FIR in cross-correlation enhancement.
  [2:0] SEL
0xA3C WIFI_ENABLEIQSYNCDET — Enable IQ sync detect monitoring.
  [1] ENABLENE — Enables the generation of an event on the negative edge of the IQ sync detect signal.
    0=Disabled; 1=Enabled
  [0] ENABLEPE — Enables the generation of an event on the positive edge of the IQ sync detect signal.
    0=Disabled; 1=Enabled
0xA40 WIFI_IQSYNCMODE — IQ sync mode.
  [0] MODE — This register is used to select whether the WIFI_IQSYNCTHRS register, or the internal MAX signal is used to compare the internal IQ sync signal whose output is the IQ sync detection signal.
    0=Fixed (WIFI_IQSYNCTHRS register); 1=Dynamic (Auto)
0xA44 WIFI_IQSYNCTHRS — IQ sync threshold.
  [5:0] THRS — Fixed threshold value for the IQ sync detection comparator.
0xA48 WIFI_IQSYNC ro — IQ sync signal.
  [5:0] DATA — IQ sync signal from sensitivity enhancement block.
0xA4C WIFI_IQSYNCMAX ro — IQ sync max signal.
  [5:0] DATA — IQ sync max signal from sensitivity enhancement block.
0xA50 WIFI_ENABLEIQENERGYDETWB — Enable wide band IQ energy detect monitoring.
  fields as WIFI_ENABLEIQENERGYDET
0xA54 WIFI_ENERGYDETTHRSNWB — Scaling value for wide band energy detector threshold filter.
  [3:0] THRS — Scaling value for energy detector threshold filter.
0xA58 WIFI_ENERGYDETLOWGAINWB — Lower gain for wide band energy detector threshold filter.
  [3:0] GAIN — Lower gain for energy detector threshold filter.
0xA5C WIFI_ENERGYDETHIGHGAINWB — Higher gain for wide band energy detector threshold filter.
  [3:0] GAIN — Higher gain for energy detector threshold filter.
0xA60 WIFI_ENERGYDETTHRSMINWB — Minimum value of the output of the wide band energy detector threshold filter.
  [14:0] MIN — Minimum value of the output of the energy detector threshold filter.
0xA64 WIFI_ENERGYDETTHRSMAXWB — Maximum value of the output of the wide band energy detector threshold filter.
  [14:0] MAX — Maximum value of the output of the energy detector threshold filter.
0xA68 WIFI_IQENERGYWB ro — Wide band energy detector RMS output.
  [14:0] DATA — Energy detector RMS output.
0xA6C WIFI_IQENERGYFILTWB ro — Wide band energy detector threshold filter output.
  [14:0] DATA — Energy detector threshold filter output.
0xB00 RX_RCCALIBRESULT ro — RX RC calibrator result
  [5] RX_ABB_CAL_DATA_READY — calibrator data output
  [4:0] RX_ABB_CAL_DK — calibrator data ready
